# cyt4dn register map
Vendor: Cypress Semiconductor; Series: cyt4dn; File version: 1.0
CPU: CM7 r0p1, little endian, MPU, FPU, VTOR, 3 interrupt priority bits
Registers are 32-bit, read-write, reset 0x0 unless marked. A register's access mark holds for its fields unless they carry their own. Offsets are from the block's base; [hi:lo] are bit positions; lines under a group give offsets from that group; {n}, {i} and the like mark numbered series.

## VIDEOSS0 (part 2 of 18) — Video and Graphics Subsystem
Base 0x40A00000
0x00 SUBSS group — Sub Interface
  0x10000 INFRA group — Bus Infrastructure.
    0x400 VRPU group — VRPU configuration.
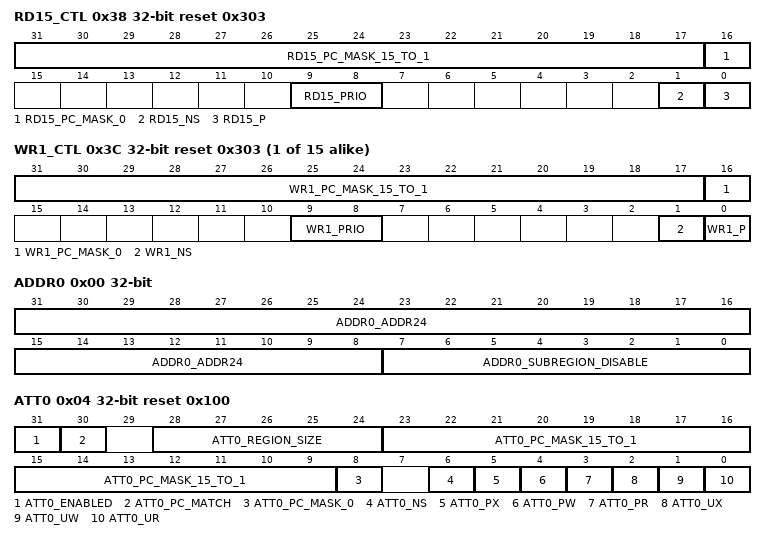
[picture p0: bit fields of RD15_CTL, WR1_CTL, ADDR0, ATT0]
      0x38 RD15_CTL reset 0x303 — VRAM Protection for read master with ID=15
        [31:17] RD15_PC_MASK_15_TO_1 — Protection context mask for protection contexts '15' downto '1'. Bit PC_MASK_15_TO_1[i] indicates if the MPU MS_CTL.PC[3:0] protection context field can be set to the value 'i+1': - PC_MASK_15_TO_1[i] is '0': MPU MS_CTL.PC[3:0] can NOT be set to 'i+1'; and PC[3:0] is not changed. If the protection context of the write transfer is '0', protection is not applied and PC[3:0] can be changed. - PC_MASK_15_TO_1[i] is '1': MPU MS_CTL.PC[3:0] can be set to 'i+1'.
        [16] RD15_PC_MASK_0 ro — Protection context mask for protection context '0'. This field is a constant '0'.
        [9:8] RD15_PRIO — Device wide bus arbitration priority setting ('0': highest priority, '3': lowest priority). Masters with the same priority setting form a 'priority group'. Within a 'priority group', roundrobin arbitration is performed.
        [1] RD15_NS — Security setting ('0': secure mode; '1': non-secure mode).
        [0] RD15_P — Privileged setting ('0': user mode; '1': privileged mode).
      {0x38+4l} WR{l}_CTL reset 0x303 (l=1..15) — VRAM Protection for write master with ID={l}
        [31:17] WR{l}_PC_MASK_15_TO_1 — Protection context mask for protection contexts '15' downto '1'. Bit PC_MASK_15_TO_1[i] indicates if the MPU MS_CTL.PC[3:0] protection context field can be set to the value 'i+1': - PC_MASK_15_TO_1[i] is '0': MPU MS_CTL.PC[3:0] can NOT be set to 'i+1'; and PC[3:0] is not changed. If the protection context of the write transfer is '0', protection is not applied and PC[3:0] can be changed. - PC_MASK_15_TO_1[i] is '1': MPU MS_CTL.PC[3:0] can be set to 'i+1'.
        [16] WR{l}_PC_MASK_0 ro — Protection context mask for protection context '0'. This field is a constant '0'.
        [9:8] WR{l}_PRIO — Device wide bus arbitration priority setting ('0': highest priority, '3': lowest priority). Masters with the same priority setting form a 'priority group'. Within a 'priority group', roundrobin arbitration is performed.
        [1] WR{l}_NS — Security setting ('0': secure mode; '1': non-secure mode).
        [0] WR{l}_P — Privileged setting ('0': user mode; '1': privileged mode).
    0x1000 VRPU_STRUCT group — VRPU structures.
      0x00 ADDR0 reset not defined
        [31:8] ADDR0_ADDR24 — See CPUSS.
        [7:0] ADDR0_SUBREGION_DISABLE — See CPUSS.
      0x04 ATT0 reset 0x100 (reset mask 0x80000100)
        [31] ATT0_ENABLED — See CPUSS.
        [30] ATT0_PC_MATCH — See CPUSS.
        [28:24] ATT0_REGION_SIZE — See CPUSS.
        [23:9] ATT0_PC_MASK_15_TO_1 — See CPUSS.
        [8] ATT0_PC_MASK_0 ro — See CPUSS.
        [6] ATT0_NS — See CPUSS.
        [5] ATT0_PX — See CPUSS.
        [4] ATT0_PW — See CPUSS.
        [3] ATT0_PR — See CPUSS.
        [2] ATT0_UX — See CPUSS.
        [1] ATT0_UW — See CPUSS.
        [0] ATT0_UR — See CPUSS.
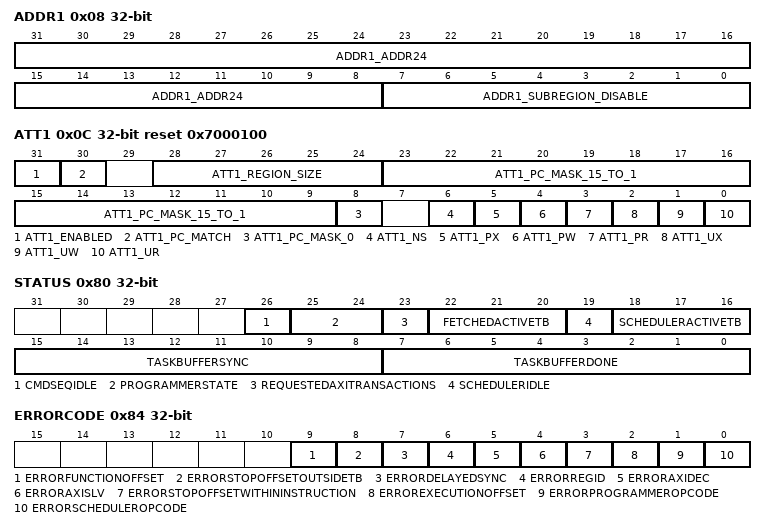
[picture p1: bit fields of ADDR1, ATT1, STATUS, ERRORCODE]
      0x08 ADDR1 ro reset not defined
        [31:8] ADDR1_ADDR24 — See CPUSS.
        [7:0] ADDR1_SUBREGION_DISABLE — See CPUSS.
      0x0C ATT1 reset 0x7000100 (reset mask 0x9F000100)
        [31] ATT1_ENABLED — See CPUSS.
        [30] ATT1_PC_MATCH — See CPUSS.
        [28:24] ATT1_REGION_SIZE ro — See CPUSS.
        [23:9] ATT1_PC_MASK_15_TO_1 — See CPUSS.
        [8] ATT1_PC_MASK_0 ro — See CPUSS.
        [6] ATT1_NS — See CPUSS.
        [5] ATT1_PX ro — See CPUSS.
        [4] ATT1_PW — See CPUSS.
        [3] ATT1_PR ro — See CPUSS.
        [2] ATT1_UX ro — See CPUSS.
        [1] ATT1_UW — See CPUSS.
        [0] ATT1_UR ro — See CPUSS.
  0x40000 GFX2D group — Graphics 2D Core
    0x00 GFX2DCFG group — Graphics 2D Core config
      0x20 INTR_GFX2D — Interrupt cause register
        [23:0] INTR_GFX2D — Interrupt status vector. A bit is set when the related event occurs or the corresponding bit of INTR_GFX2D_SET is written. By writing 1 the corresponding bit is cleared.
      0x24 INTR_GFX2D_SET wo — Interrupt set register
        [23:0] INTR_GFX2D_SET — Interrupt set vector. Writing a 1 to this field sets the corresponding bit of INTR_GFX2D.
      0x28 INTR_GFX2D_MASK — Interrupt mask register
        [23:0] INTR_GFX2D_MASK — Interrupt mask vector. Please note that this enable vector does not affect the INTR0 register field. It only affects INTR_GFX2D_MASKED.
      0x2C INTR_GFX2D_MASKED ro reset not defined — Interrupt masked register
        [23:0] INTR_GFX2D_MASKED — Status vector that generates the interrupt to the CPU if at least one bit of this field is set. This field corresponds to the bit-wise AND between INTR_GFX2D and INTR_GFX2D_MASK fields.
      0x30 INTR_CMDSEQ — Interrupt cause register for CmdSeq
        [21:0] INTR_CMDSEQ — Interrupt status vector. A bit is set when the related event occurs or the corresponding bit of INTR_CMDSEQ_SET is written. By writing 1 the corresponding bit is cleared.
      0x34 INTR_CMDSEQ_SET wo — Interrupt set register
        [21:0] INTR_CMDSEQ_SET — Interrupt set vector. Writing a 1 to this field sets the corresponding bit of INTR_CMDSEQ.
      {0x40+4l} GENERALPURPOSE[{l}] (l=0..15) reset not defined — General purpose config memory
        [31:0] GENERALPURPOSE — General purpose config memory entry, does not have any function.
    0x10000 CMDSEQ group — Command Sequencer
      {0x0+0xC*l} TASKBUFFERADDRESS{l} (l=0..7) — Task buffer {l} address register
        [31:3] ADDRESSTB{l} — Task buffer {l} base address in multiple of 64-bit words.
      {0x4+0xC*l} TASKBUFFERSIZE{l} (l=0..7) — Task buffer {l} size register
        [15:0] SIZETB{l} — Task buffer {l} size in multiple of 32-bit words. The maximal size of task buffer equals to 4 * (2^16 - 1) bytes. The minimal size required to start execution is 2, because the minimal value of the stop offset is 1 and it has to be smaller then the task buffer size.
      {0x8+0xC*l} TASKBUFFERSTOPOFFSET{l} (l=0..7) — Task buffer {l} stop offset register
        [15:0] STOPOFFSETTB{l} — Task buffer {l} stop offset in multiple of 32-bit words to determine the last valid scheduling instruction. Only scheduling instructions up to this offset are executed or with other words instruction at the StopOffset-1 is the last instruction which is executed.
      {0x60+4l} TASKBUFFEREXECOFFSET{l} ro reset not defined (l=0..7) — Task buffer {l} execute offset register
        [15:0] EXECOFFSETTB{l} — Task buffer {l} execution offset in multiple of 32-bit words. Offset of the scheduling instruction that is to be executed next. Instruction at adress = AddressTB{l} has offset zero.
      0x80 STATUS ro reset not defined
        [26] CMDSEQIDLE — CmdSeq is not processing any instructions and there are no outstanding AXI transactions.
        [25:24] PROGRAMMERSTATE — Execution state of programmer
          0=IDLE (When all fetched instructions have been executed and there are no functions scheduled for the execution); 1=SYNC (During execution of the SYNC instruction); 2=ACTIVE (Execution of instructions); 3=AXI_WAIT (There is function scheduled for the execution, but the internal instruction buffer is empty.)
        [23] REQUESTEDAXITRANSACTIONS — There are some outstanding axi transactions that have been requested but are not received yet.
        [22:20] FETCHEDACTIVETB — Task buffer beeing fetch last in programmer. If programmer is in idle state, the value of this field is not valid.
        [19] SCHEDULERIDLE — Scheduler is not processing any instructions and there are no outstanding AXI transactions.
        [18:16] SCHEDULERACTIVETB — Task buffer beeing executed in scheduler. If scheduler is in idle state, the value of this field is not valid.
        [15:8] TASKBUFFERSYNC — Each bit corresponds to one task buffer. '1' means that the scheduling of corresponding TB is blocked until some SW or HW state is reached.
        [7:0] TASKBUFFERDONE — Each bit corresponds to one task buffer. '1' means that the ExecOffset equals to the StopOffset
      0x84 ERRORCODE ro reset not defined — Error code register, each field of this register is one bit wide and corresponds to an error event. If the value of this register is zero, than there are no errors.
        [9] ERRORFUNCTIONOFFSET — Function offset provided by the EXEC instruction is outside of task buffer
        [8] ERRORSTOPOFFSETOUTSIDETB — Stop offset value is bigger than or equals to task buffer size. If however both are zero, no error should be raised.
        [7] ERRORDELAYEDSYNC — SYNC is following delayed SYNC in Scheduler
        [6] ERRORREGID — Error accessing an register via id that is not bound to any GPR or SPR register
        [5] ERRORAXIDEC — AXI decoder error has been occured. SchedulerAddress and ProgrammerAddress have to be evaluated
        [4] ERRORAXISLV — AXI slave error has been occured. SchedulerAddress and ProgrammerAddress have to be evaluated
        [3] ERRORSTOPOFFSETWITHININSTRUCTION — Stop offset is within instruction in scheduler
        [2] ERROREXECUTIONOFFSET — Execution offset is outside of the task buffer
        [1] ERRORPROGRAMMEROPCODE — Opcode error in programmer
        [0] ERRORSCHEDULEROPCODE — Opcode error in scheduler
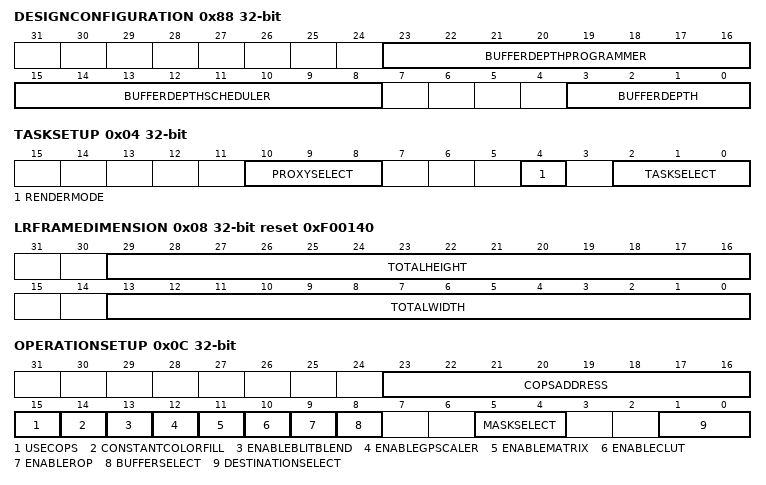
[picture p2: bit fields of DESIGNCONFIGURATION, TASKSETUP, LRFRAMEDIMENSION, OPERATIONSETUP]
      0x88 DESIGNCONFIGURATION ro reset not defined — Provides HW specific information.
        [23:16] BUFFERDEPTHPROGRAMMER — The buffer (axi decouple fifo) size inside of the programmer.
        [15:8] BUFFERDEPTHSCHEDULER — The buffer (axi decouple fifo) size inside of the scheduler.
        [3:0] BUFFERDEPTH — The size of the buffer between the Scheduler and the Programmer.
      0x8C SCHEDULERADDRESS ro reset not defined — Last fetched address of scheduler.
        [31:0] SCHEDULERADDRESS — Last fetched address of scheduler
      0x90 PROGRAMMERADDRESS ro reset not defined — Last fetched address of programmer.
        [31:0] PROGRAMMERADDRESS — Last fetched address of programmer
      {0x94+4l} GPR{l} ro reset not defined (l=0..15) — GeneralPurpose Register. (Internal register with id = {l})
        [31:0] GENERALPURPOSEREGISTER{l} — General Purpose Register used internally for CmdSeq and for syncronization with SW.
      0xD4 SPR0 ro reset not defined — Special Purpose Register. (Internal register with id = 16)
        [15:0] LINECOUNTERTB0 — Holds the scheduled line of the frame that is beeing executed in TB0. The value of this register is routed outside CmdSeq.
      {0xD4+4l} SPR{l} ro reset not defined (l=1..7) — Special Purpose Register (internal register with id = {l+16})
        [15:0] LINECOUNTERTB{l} — Holds the scheduled line of the frame that is beeing executed in TB{l}. The value of this register is routed outside CmdSeq.
    0x20000 BLITENG group — Blit Engine
      0x00 BLITENGCFG group — Top-Level
        0x00 STATICCONTROL
          [5:4] LRSTATUSSELECT — Select pipeline from which to access status register information in line-rendering mode.
          [2] SLICEPERFMEASUREMENTEN — Enable performance measument per slice in blit engine.
          [1] PERFMEASUREMENTEN — Enable global performance measument in blit engine.
          [0] SHDEN — Enables shadowing of all RWS type registers (0=write_through, 1=shadowed). For LBO this ShdEn and ShdEn fields of all modules inside Bliteng have to be 1.
        0x04 TASKSETUP — Task configuration register.
          [10:8] PROXYSELECT — Proxy to use for the next operation
            0=OFF (Proxy disabled.); {v}=FETCHLBH{v-1} (Proxy connected to FETCHLBH{v-1}.) (v=1..5)
          [4] RENDERMODE — Blit engine operation mode.
            0=FRAMERENDERING (Frame rendering mode (framebuffer).); 1=LINERENDERING (Line rendering mode (linebuffer).)
          [2:0] TASKSELECT — Select task bank for operation status registers (ypos, ...).
        0x08 LRFRAMEDIMENSION reset 0xF00140 — Dimension of final frame in memory.
          [29:16] TOTALHEIGHT — Frame height (programmed with -1).
          [13:0] TOTALWIDTH — Frame width (programmed with -1).
        0x0C OPERATIONSETUP — Setup for rendering operation.
          [23:16] COPSADDRESS — Address to use in Current Object Processing State (COPS) memory (required for decode operations). Only possible in LBO mode.
          [15] USECOPS — Cops are used for the next fetch operation. If the value is zero, CopsAddress is not evaluated. Only possible in LBO mode.
          [14] CONSTANTCOLORFILL — If this field is set, the selected destination (BufferSelect) will be filled with constant color (ConstantColorRed, ConstantColorGreen, ConstantColorBlue, ConstantAlpha) not using any fetch pipeline. Only possible in LBO mode.
          [13] ENABLEBLITBLEND — Set 1 enable the BlitBlend module. If this field is set
          [12] ENABLEGPSCALER — Set 1 enable GPScaler. This field is ignored for LBO render mode.
          [11] ENABLEMATRIX — Set 1 to enable matrix.
          [10] ENABLECLUT — Set 1 to enable CLUT. This field is ignored for LBO render mode.
          [9] ENABLEROP — Set 1 to enable ROP module. This field is ignored for LBO render mode.
          [8] BUFFERSELECT — Line buffer to render into. This field is ignored for IBO render mode.
            0=RGBA (RGBA buffer.); 1=MASK (MASK buffer.)
          [5:4] MASKSELECT — Select operation for mask buffer. In IBO the buffer is provided via the FETCHMASK; in LBO the buffer is provided via internal ALPHA slice buffer. If the value of both fields this and DestinationSelect is BLEND, OFF is used for this field.
            0=OFF (Mask buffer is not read.); 1=ROP (Mask is connected to raster operation block (secondary). Only possible in IBO mode.); 2=BLEND (Mask is connected to blend operation block. Only possible in LBO mode.); 3=FETCHSRC (Mask is connected to the fetch SRC.)
          [1:0] DESTINATIONSELECT — Select operation for destination buffer. In IBO the buffer is provided via the FETCHDST in LBO the buffer is provided via internal RGBA slice buffer.
            0=OFF (Destination buffer is not read, used for FILL or COPY operations.); 1=ROP (Destination is connected to raster operation block (tertary). Only possible in IBO mode.); 2=BLEND (Destination is connected to blend operation block.); 3=FETCHMASK (Destination fetch is connected to the external input of the fetch MASK, for planar YUV. Only possible in IBO mode.)
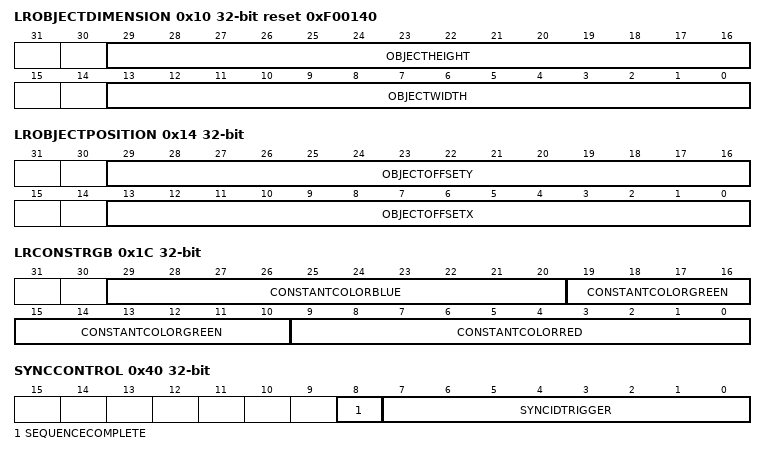
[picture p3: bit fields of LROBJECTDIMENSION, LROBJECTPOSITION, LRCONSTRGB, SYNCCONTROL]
        0x10 LROBJECTDIMENSION reset 0xF00140 — Dimension of object. Only possible in LBO mode
          [29:16] OBJECTHEIGHT — Object height (programmed with -1).
          [13:0] OBJECTWIDTH — Object width (programmed with -1).
        0x14 LROBJECTPOSITION — Position of current object in frame coordinate system. Only possible in LBO mode
          [29:16] OBJECTOFFSETY — Object position in y direction (start at 0).
          [13:0] OBJECTOFFSETX — Object position in x direction (start at 0).
        0x18 LRCONSTALPHA — Constant alpha used to fill buffer w/o fetch unit. Has affect only if ConstantColorFill is set. Only possible in LBO mode.
          [7:0] CONSTANTALPHA — Alpha to be filled to RGBA or Alpha buffer.
        0x1C LRCONSTRGB — Constant color used to fill buffer w/o fetch unit. Has affect only if ConstantColorFill is set and BufferSelect==RGBA. Only possible in LBO mode
          [29:20] CONSTANTCOLORBLUE — Constant blue color to be filled into RGBA buffer.
          [19:10] CONSTANTCOLORGREEN — Constant green color to be filled into RGBA buffer.
          [9:0] CONSTANTCOLORRED — Constant red color to be filled into RGBA buffer.
        {0x20+4m} SYNCIDREQUEST{m} (m=0..7) — Sync ID request register.
          [31:0] SYNCIDREQUEST{m} — Sync ID requested by SW. Will be loaded into SyncIdStatus{m} if SyncIdTrigger[{m}] is set and if/once store operation is done.
        0x40 SYNCCONTROL wo — Triggers interrupts for sequence complete of specific TB of global sequence complete interrupt.
          [8] SEQUENCECOMPLETE — Trigger SeqComplete interrupt if BlitEng is idle or the last oparation has been completed.
          [7:0] SYNCIDTRIGGER — Trigger SyncIdComplete[0:7] and load SyncIdRequest[0:7] into SyncIdStatus[0:7]. Is executed after store operation is completed or no operation is active on the corresponding TB.
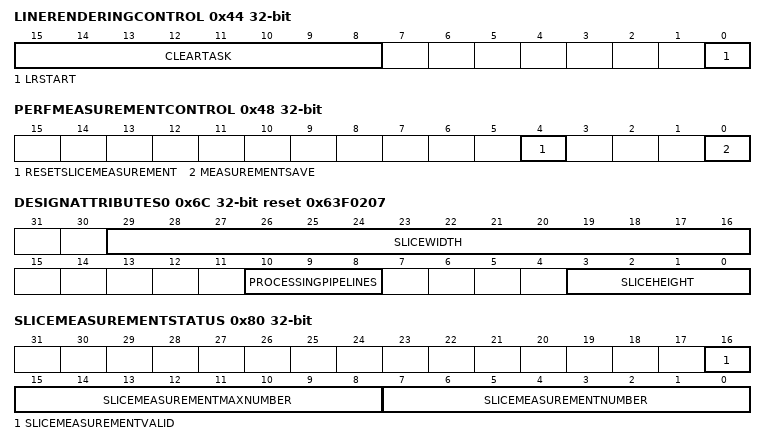
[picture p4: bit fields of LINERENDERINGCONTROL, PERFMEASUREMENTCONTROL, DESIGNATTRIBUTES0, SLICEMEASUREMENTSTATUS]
        0x44 LINERENDERINGCONTROL wo reset not defined — Line rendering operation control register.
          [15:8] CLEARTASK — Clear related registers (ypos, perf) of corresponding TB. Each bit corresponds to one TB.
          [0] LRSTART — Start next source to linebuffer operation.
        0x48 PERFMEASUREMENTCONTROL wo reset not defined — Control register of the performance measurement counters ClockCounter and IdleCounter
          [4] RESETSLICEMEASUREMENT — Restarts the slice measurement from the next slice.
          [0] MEASUREMENTSAVE — This flag goes high when the clock_count counter (LineRenderingClockCnt register) has overflow.
        {0x4C+4m} SYNCIDSTATUS{m} ro reset not defined (m=0..7) — Sync ID Status register for task {m}.
          [31:0] SYNCIDCOMPLETE{m} — Latest ID completed as requested by SyncIdRequest and SyncIdTrigger with TaskSelect = {m}.
        0x6C DESIGNATTRIBUTES0 ro reset 0x63F0207 — This register contains attributes of Bliteng. They are not parameters since they cannot be easily changed, however here we still have them to provide some static status on design.
          [29:16] SLICEWIDTH — Returns the maximum width that can be rendert in LBO mode minus one.
          [10:8] PROCESSINGPIPELINES — Returns the maximum number of pixel processing pipelines LBO mode minus one.
          [3:0] SLICEHEIGHT — Returns the slice height mode minus one.
        0x70 DESIGNATTRIBUTES1 ro reset 0x63F — This register contains attributes of Bliteng. They are not parameters since they cannot be easily changed, however here we still have them to provide some static status on design.
          [13:0] GPSCALERWIDTH — Returns the maximum width that can be rendert in LBO mode minus one.
        0x74 PERFMEASUREMENTCLOCKCOUNTERRUNNING ro reset not defined — Performance measurement register for BlitEng containing clock cycle counter. Measurement is active only if PerfMeasurementEn is set.
          [31:0] CLOCKCOUNTERRUNNING — ClockCounterRunning is incremented each clock cycle.
        0x78 PERFMEASUREMENTCLOCKCOUNTER ro reset not defined — Performance measurement register for BlitEng containing clock cycle counter. Measurement is active only if PerfMeasurementEn is set.
          [31:0] CLOCKCOUNTER — When ClockCounterRunning has overrun or MeasurementSave has been triggered the value of clock counter is written to this register.
        0x7C PERFMEASUREMENTIDLECOUNTER ro reset not defined — Performance measurement register for BlitEng containing idle cycles. Measurement is active only if PerfMeasurementEn is set.
          [31:0] IDLECOUNTER — Idle counter is incremented with each clock cycle when blitEng is in idle state. When ClockCounter has overrun or MeasurementSave has been triggered idle counter is written to this register.
        0x80 SLICEMEASUREMENTSTATUS ro reset not defined — Performance measurement register for BlitEng containing idle cycles. Measurement is active only if SlicePerfMeasurementEn is set.
          [16] SLICEMEASUREMENTVALID — This bit is one if the results of measurement are valid. If this bit is zero, the mesurement is stopped and has to be restarted via SlicePerfMeasurementEn.
          [15:8] SLICEMEASUREMENTMAXNUMBER — The maximal number of slice measurements that can be stored.
          [7:0] SLICEMEASUREMENTNUMBER — The number of measurements that can be read from SliceMeasurementValues register. Incremented with each slice being finished and decremented after each read from SliceMeasurementValues.
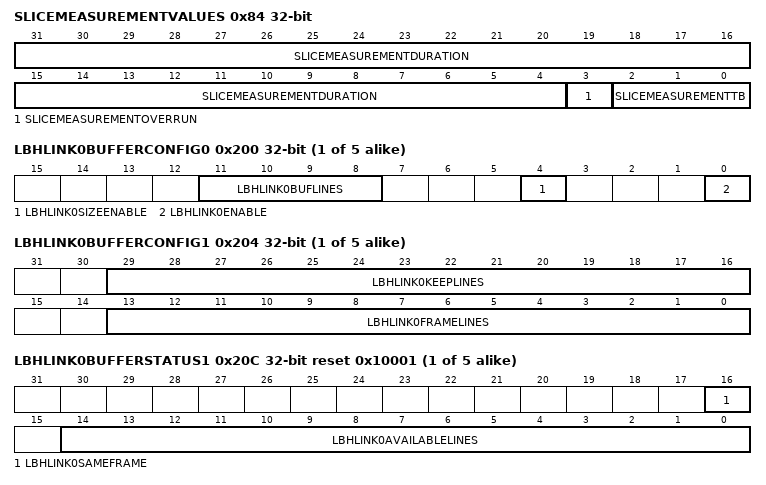
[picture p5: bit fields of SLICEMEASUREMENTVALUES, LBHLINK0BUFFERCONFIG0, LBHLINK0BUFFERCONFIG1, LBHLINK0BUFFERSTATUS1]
        0x84 SLICEMEASUREMENTVALUES reset not defined — Performance measurement for each slice. Measurement is active only if SlicePerfMeasurementEn is set. This register can be always read,
          [31:4] SLICEMEASUREMENTDURATION — The measured duration of the slice in clock cylces
          [3] SLICEMEASUREMENTOVERRUN — The measured slice duration is not valid because of the overrun. The measurement itself can continue, all other slice durations are still valid.
          [2:0] SLICEMEASUREMENTTB — The id of taskbuffer to which this measurement corresponds.
        0x100 LBHGLOBAL — Settings common for all line-buffer handshake connections.
          [0] LBHCYCLECOUNTERENABLE — Enable performance counters. [Note] these counters should be enabled when the link is already active
        0x104 LBHGLOBALSTATUS0 ro reset not defined — Global status register 0 for the line buffer handshake.
          [31:0] LBHCYCLECOUNTER — This counter increments with every clock cycle.
        0x108 LBHGLOBALSTATUS1 ro reset not defined — Global status register 1 for the line buffer handshake.
          [31:0] LBHREADYCYCLES — This counter increments with every cycle a slice is allowed to be written to any line buffer.
        0x10C LBHGLOBALSTATUS2 ro reset not defined — Global status register 2 for the line buffer handshake.
          [0] LBHCYCLECOUNTEROVERFLOW — This flag is raised when overflow occurs on the LbhCycleCounter.
        {0x200+0x40*m} LBHLINK{m}BUFFERCONFIG0 (m=0..4) — Line buffer configuration register 0.
          [11:8] LBHLINK{m}BUFLINES — The number of lines in the line buffer in power of two. Max supported number of lines in ringbuffer is 16384 (14pow2=16384). Programming 15 results also in 16384 lines.
          [4] LBHLINK{m}SIZEENABLE — Activates the ring buffer usage. This signal will be provided to the fetch and the store.
          [0] LBHLINK{m}ENABLE — Activates the line-buffer handshake, i.e. will stall the store or the display fetch upon respective condition.
        {0x204+0x40*m} LBHLINK{m}BUFFERCONFIG1 (m=0..4) — Line buffer configuration register 1.
          [29:16] LBHLINK{m}KEEPLINES — Number of lines to keep in the line buffer even if the display fetch is already beyond this line. Required for re-sampling operations that span over several input lines.
          [13:0] LBHLINK{m}FRAMELINES — Height of the frame (programmed with -1). This setting must be identical to the display fetch and BlitEng value.
        {0x208+0x40*m} LBHLINK{m}BUFFERSTATUS0 (m=0..4) — Buffer status register 0 for the line buffer handshake.
          [14:0] LBHLINK{m}MAXFREELINES — The maximal number of free lines in the line buffer that can be written by the store. Writting to this register has no effect, reading provides the value and simultaneously resets the register.
        {0x20C+0x40*m} LBHLINK{m}BUFFERSTATUS1 ro reset 0x10001 (m=0..4) — Buffer status register 1 for the line buffer handshake.
          [16] LBHLINK{m}SAMEFRAME — This status bit indicates if the fetch and the store are processing the same frame. If this bit is zero the store has already switched to the next frame
          [14:0] LBHLINK{m}AVAILABLELINES — The number of lines in the line buffer that the store can write.
        {0x210+0x40*m} LBHLINK{m}BUFFERSTATUS2 ro reset not defined (m=0..4) — Buffer status register 2 for the line buffer handshake.
          [31:0] LBHLINK{m}BUFFERREADYCYCLES — This counter increments with every cycle a slice is allowed to be written to the line buffer.
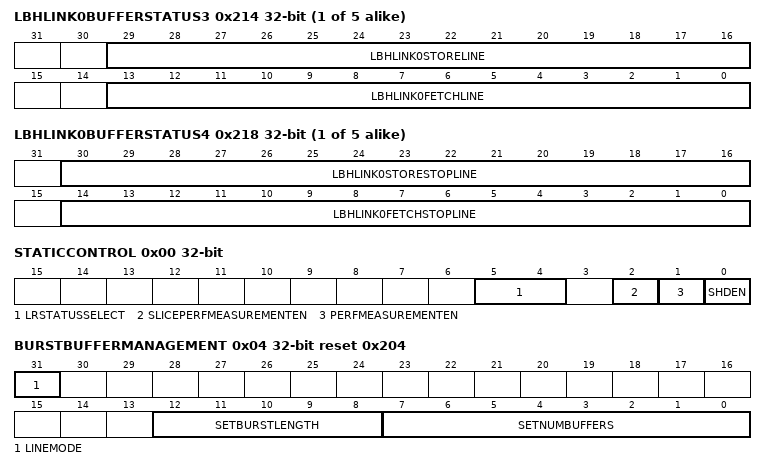
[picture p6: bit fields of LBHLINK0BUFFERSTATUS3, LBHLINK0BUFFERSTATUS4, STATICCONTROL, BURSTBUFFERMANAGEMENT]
        {0x214+0x40*m} LBHLINK{m}BUFFERSTATUS3 ro reset not defined (m=0..4) — Buffer status register 3 for the line buffer handshake.
          [29:16] LBHLINK{m}STORELINE — This field describes the line currently written by the store.
          [13:0] LBHLINK{m}FETCHLINE — This field describes the line currently read by the display fetch.
        {0x218+0x40*m} LBHLINK{m}BUFFERSTATUS4 ro reset not defined (m=0..4) — Buffer status register 4 for the line buffer handshake.
          [30:16] LBHLINK{m}STORESTOPLINE — This field describes the stopline of the store.
          [14:0] LBHLINK{m}FETCHSTOPLINE — This field describes the stopline of the display fetch.
        {0x2000+4m} PALETTE[{m}] (m=0..2047) — Shared Palette Memory.
          [23:0] PALETTEENTRY — Shared palette entry with 24-bit. Color format can be defined by Fetch configuration.
      0x4000 FETCHSRC group
        0x00 STATICCONTROL — Common static control options.
          [23:16] BASEADDRESSAUTOUPDATE — Enable flag for continuous shadow load of BaseAddress field for each layer (layer index = bit index). When set to 1 the active BaseAddress configuration is loaded from shadow at start of each frame. This update is then executed independently from other RWS type fields. ShdEn must be enabled for this mode. When the flag is enabled for layer 0, also the FieldId0 shadow is automatically loaded.
          [0] SHDEN — Enables shadowing of all RWS type registers (0=write_through, 1=shadowed).
        0x04 BURSTBUFFERMANAGEMENT reset 0x204 — AXI interface buffer management register
          [31] LINEMODE — Fetch buffer cache control.
            0=DISPLAY (Mandatory setting for operation in the Display Controller. Works also for Blit Engine with marginal performance impact.); 1=BLIT (Recommended setting for operation in the Blit Engine.)
          [12:8] SETBURSTLENGTH — Set this to the burst length that should be used on the AXI interface. SetNumBuffers * SetBurstLength has to be smaller or equal to ManagedBurstBuffers * BurstLengthForMaxBuffers and that bursts larger than 16 are not possible on the axi interface. Only a power of two may be specified as burst length.
          [7:0] SETNUMBUFFERS — Set this to the number of bursts that should be buffered. SetNumBuffers has to be smaller or equal to ManagedBurstBuffers and SetNumBuffers * SetBurstLength has to be smaller or equal to ManagedBurstBuffers * BurstLengthForMaxBuffers. Must be a power of 2. The minimum allowed settings is 4 except for the fetcheco derivate which has a minimum allowed setting of 2.
